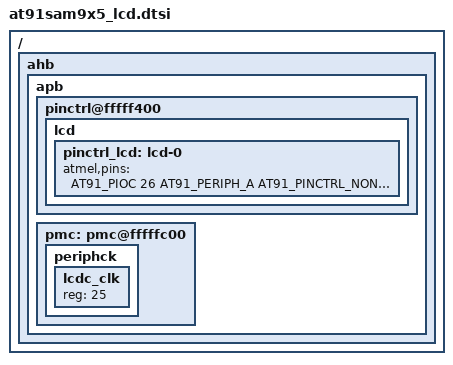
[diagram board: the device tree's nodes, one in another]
/*
 * at91sam9x5_lcd.dtsi - Device Tree Include file for AT91SAM9x5 SoC with an
 * LCD controller.
 *
 * Copyright (C) 2013 Boris BREZILLON <b.brezillon@overkiz.com>
 *
 * Licensed under GPLv2.
 */

#include <dt-bindings/pinctrl/at91.h>
#include <dt-bindings/interrupt-controller/irq.h>

/ {
	ahb {
		apb {
			pinctrl@fffff400 {
				lcd {
					pinctrl_lcd: lcd-0 {
						atmel,pins =
							<AT91_PIOC 26 AT91_PERIPH_A AT91_PINCTRL_NONE	/* PC26 periph A LCDPWM */
							 AT91_PIOC 27 AT91_PERIPH_A AT91_PINCTRL_NONE	/* PC27 periph A LCDVSYNC */
							 AT91_PIOC 28 AT91_PERIPH_A AT91_PINCTRL_NONE	/* PC28 periph A LCDHSYNC */
							 AT91_PIOC 24 AT91_PERIPH_A AT91_PINCTRL_NONE	/* PC24 periph A LCDDISP */
							 AT91_PIOC 29 AT91_PERIPH_A AT91_PINCTRL_NONE	/* PC29 periph A LCDDEN */
							 AT91_PIOC 30 AT91_PERIPH_A AT91_PINCTRL_NONE	/* PC30 periph A LCDPCK */
							 AT91_PIOC 0 AT91_PERIPH_A AT91_PINCTRL_NONE	/* PC0 periph A LCDD0 pin */
							 AT91_PIOC 1 AT91_PERIPH_A AT91_PINCTRL_NONE	/* PC1 periph A LCDD1 pin */
							 AT91_PIOC 2 AT91_PERIPH_A AT91_PINCTRL_NONE	/* PC2 periph A LCDD2 pin */
							 AT91_PIOC 3 AT91_PERIPH_A AT91_PINCTRL_NONE	/* PC3 periph A LCDD3 pin */
							 AT91_PIOC 4 AT91_PERIPH_A AT91_PINCTRL_NONE	/* PC4 periph A LCDD4 pin */
							 AT91_PIOC 5 AT91_PERIPH_A AT91_PINCTRL_NONE	/* PC5 periph A LCDD5 pin */
							 AT91_PIOC 6 AT91_PERIPH_A AT91_PINCTRL_NONE	/* PC6 periph A LCDD6 pin */
							 AT91_PIOC 7 AT91_PERIPH_A AT91_PINCTRL_NONE	/* PC7 periph A LCDD7 pin */
							 AT91_PIOC 8 AT91_PERIPH_A AT91_PINCTRL_NONE	/* PC8 periph A LCDD8 pin */
							 AT91_PIOC 9 AT91_PERIPH_A AT91_PINCTRL_NONE	/* PC9 periph A LCDD9 pin */
							 AT91_PIOC 10 AT91_PERIPH_A AT91_PINCTRL_NONE	/* PC10 periph A LCDD10 pin */
							 AT91_PIOC 11 AT91_PERIPH_A AT91_PINCTRL_NONE	/* PC11 periph A LCDD11 pin */
							 AT91_PIOC 12 AT91_PERIPH_A AT91_PINCTRL_NONE	/* PC12 periph A LCDD12 pin */
							 AT91_PIOC 13 AT91_PERIPH_A AT91_PINCTRL_NONE	/* PC13 periph A LCDD13 pin */
							 AT91_PIOC 14 AT91_PERIPH_A AT91_PINCTRL_NONE	/* PC14 periph A LCDD14 pin */
							 AT91_PIOC 15 AT91_PERIPH_A AT91_PINCTRL_NONE	/* PC15 periph A LCDD15 pin */
							 AT91_PIOC 16 AT91_PERIPH_A AT91_PINCTRL_NONE	/* PC16 periph A LCDD16 pin */
							 AT91_PIOC 17 AT91_PERIPH_A AT91_PINCTRL_NONE	/* PC17 periph A LCDD17 pin */
							 AT91_PIOC 18 AT91_PERIPH_A AT91_PINCTRL_NONE	/* PC18 periph A LCDD18 pin */
							 AT91_PIOC 19 AT91_PERIPH_A AT91_PINCTRL_NONE	/* PC19 periph A LCDD19 pin */
							 AT91_PIOC 20 AT91_PERIPH_A AT91_PINCTRL_NONE	/* PC20 periph A LCDD20 pin */
							 AT91_PIOC 21 AT91_PERIPH_A AT91_PINCTRL_NONE	/* PC21 periph A LCDD21 pin */
							 AT91_PIOC 22 AT91_PERIPH_A AT91_PINCTRL_NONE	/* PC22 periph A LCDD22 pin */
							 AT91_PIOC 23 AT91_PERIPH_A AT91_PINCTRL_NONE>;	/* PC23 periph A LCDD23 pin */
					};
				};
			};

			pmc: pmc@fffffc00 {
				periphck {
					lcdc_clk: lcdc_clk {
						#clock-cells = <0>;
						reg = <25>;
					};
				};
			};
		};
	};
};
